AUTOSAR XML (schema 4-2-2)
package /Components
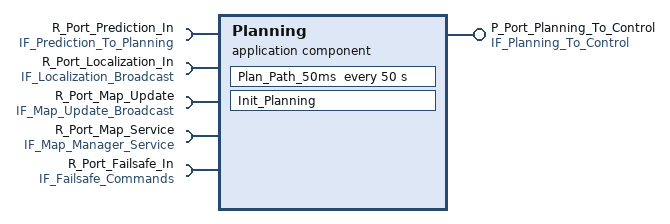
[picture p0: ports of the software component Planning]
  application sw component type Planning
    provide port P_Port_Planning_To_Control: provided-interface=IF_Planning_To_Control
    5 x require port:
      R_Port_Prediction_In: required-interface=IF_Prediction_To_Planning
      R_Port_Localization_In: required-interface=IF_Localization_Broadcast
      R_Port_Map_Update: required-interface=IF_Map_Update_Broadcast
      R_Port_Map_Service: required-interface=IF_Map_Manager_Service
      R_Port_Failsafe_In: required-interface=IF_Failsafe_Commands
    behavior Planning_InternalBehavior
      init event Planning_Init: start-on-event=Init_Planning
      timing event Planning_50ms: start-on-event=Plan_Path_50ms, period=50
      runnable Init_Planning
        parameter access InitParamAccess_Localization_Status: accessed-parameter=R_Port_Localization_In.Localization_Status
      runnable Plan_Path_50ms: minimum-start-interval=50
        data-receive-point-by-arguments:
          access Read_Predicted_Trajectories: accessed-variable=R_Port_Prediction_In.Predicted_Trajectories
          access Read_Ego_Pose: accessed-variable=R_Port_Localization_In.Ego_Pose
        data-send-points:
          access Send_Target_Trajectory: accessed-variable=P_Port_Planning_To_Control.Target_Trajectory
          access Send_Speed_Profile: accessed-variable=P_Port_Planning_To_Control.Speed_Profile
          access Send_Behavior_Cmd: accessed-variable=P_Port_Planning_To_Control.Behavior_Cmd
        parameter access RuntimeParamAccess_Map_Version: accessed-parameter=R_Port_Map_Update.Map_Version
        sync call Call_GetHDMapTile: operation=R_Port_Map_Service.GetHDMapTile, timeout=30
        sync call Call_GetLaneAttributes: operation=R_Port_Map_Service.GetLaneAttributes, timeout=30
